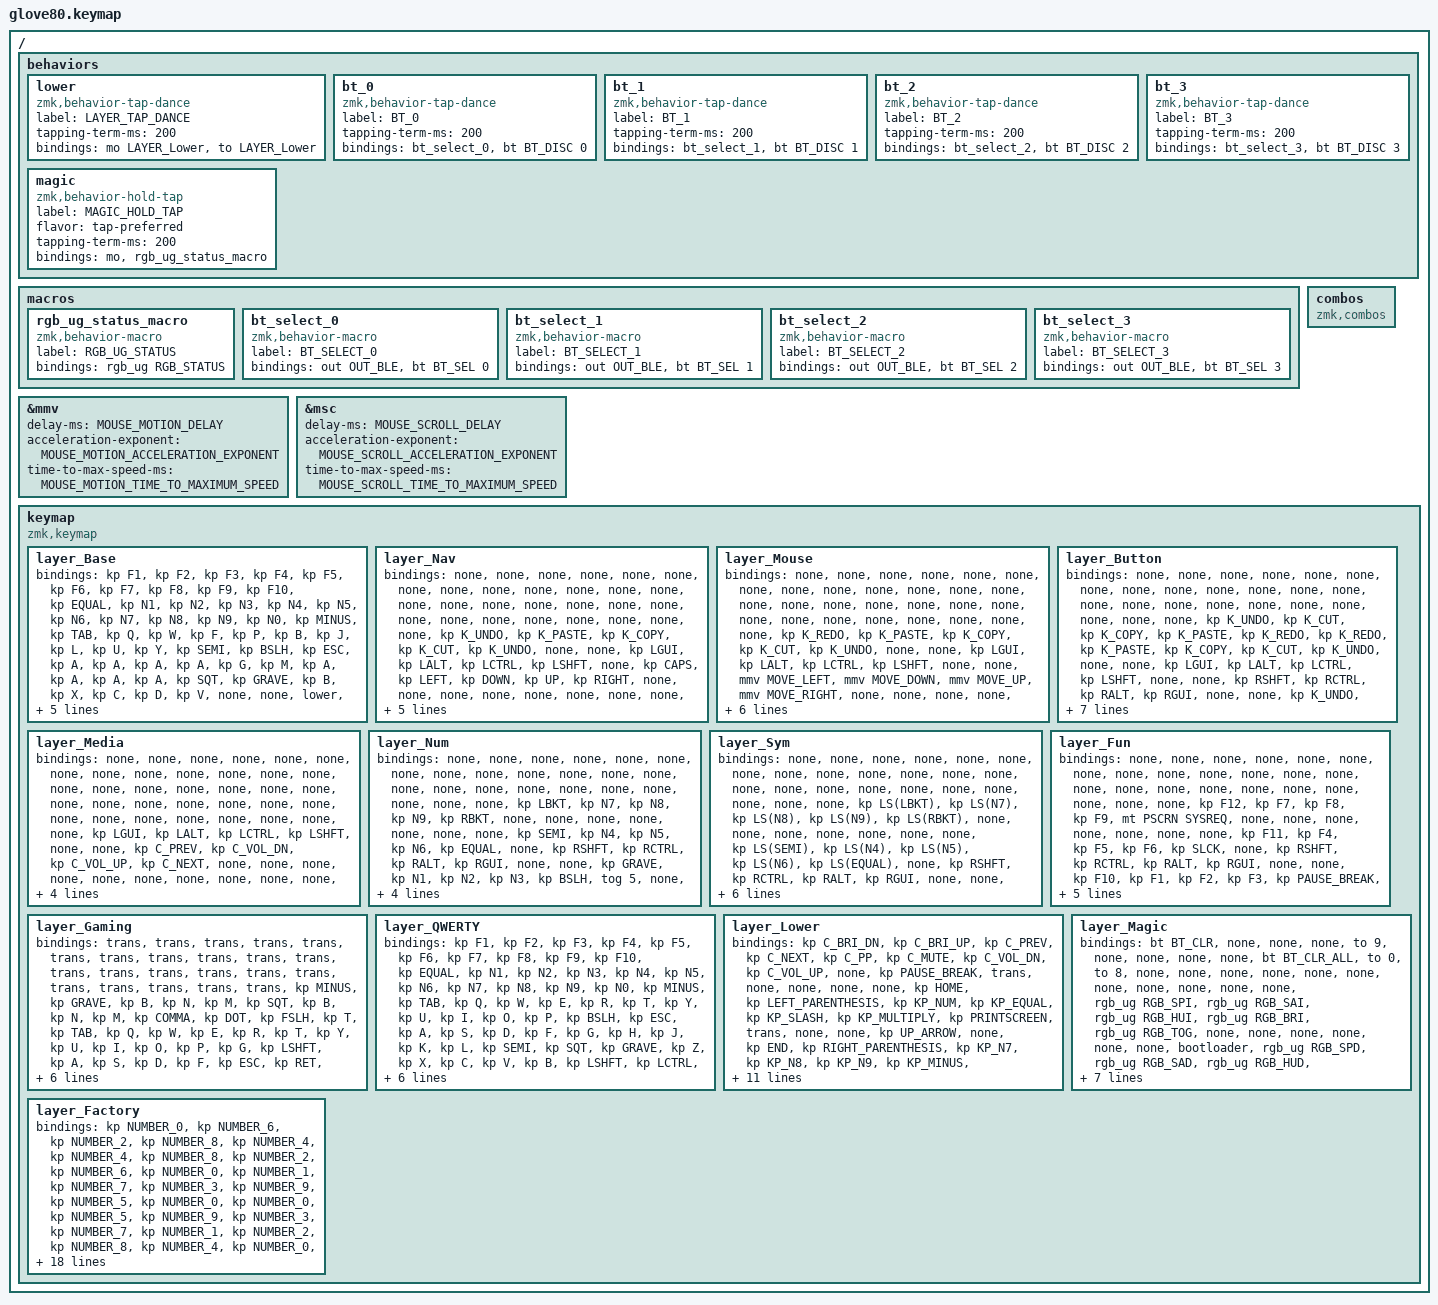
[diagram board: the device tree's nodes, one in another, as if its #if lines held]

/*
 * Copyright (c) 2020 The ZMK Contributors
 * Copyright (c) 2023 Innaworks Development Limited, trading as MoErgo
 *
 * SPDX-License-Identifier: MIT
 */


/* THIS FILE WAS GENERATED BY GLOVE80 LAYOUT EDITOR
 *
 * This file was generated automatically. You may or may not want to
 * edit it directly.
 */

#include <behaviors.dtsi>
/* Include all behavior includes needed */
#include <dt-bindings/zmk/outputs.h>
#include <dt-bindings/zmk/keys.h>
#include <dt-bindings/zmk/bt.h>
#include <dt-bindings/zmk/rgb.h>

/* Automatically generated layer name #define */
#define LAYER_Base 0
#define LAYER_Nav 1
#define LAYER_Mouse 2
#define LAYER_Button 3
#define LAYER_Media 4
#define LAYER_Num 5
#define LAYER_Sym 6
#define LAYER_Fun 7
#define LAYER_Gaming 8
#define LAYER_QWERTY 9
#define LAYER_Lower 10
#define LAYER_Magic 11
#define LAYER_Factory 12

/* To deal with the situation where there is no Lower layer, to keep &lower happy */
#ifndef LAYER_Lower
#define LAYER_Lower 0
#endif

/* Custom Device-tree */



/* Glove80 system behavior & macros */
/ {
    behaviors {
        // For the "layer" key, it'd nice to be able to use it as either a shift or a toggle.
        // Configure it as a tap dance, so the first tap (or hold) is a &mo and the second tap is a &to
        lower: lower {
            compatible = "zmk,behavior-tap-dance";
            label = "LAYER_TAP_DANCE";
            #binding-cells = <0>;
            tapping-term-ms = <200>;
            bindings = <&mo LAYER_Lower>, <&to LAYER_Lower>;
        };
    };
};

/ {
    macros {
        rgb_ug_status_macro: rgb_ug_status_macro {
            label = "RGB_UG_STATUS";
            compatible = "zmk,behavior-macro";
            #binding-cells = <0>;
            bindings
                = <&rgb_ug RGB_STATUS>;
        };
    };
};


/ {
#ifdef BT_DISC_CMD
    behaviors {
        bt_0: bt_0 {
            compatible = "zmk,behavior-tap-dance";
            label = "BT_0";
            #binding-cells = <0>;
            tapping-term-ms = <200>;
            bindings = <&bt_select_0>, <&bt BT_DISC 0>;
        };
        bt_1: bt_1 {
            compatible = "zmk,behavior-tap-dance";
            label = "BT_1";
            #binding-cells = <0>;
            tapping-term-ms = <200>;
            bindings = <&bt_select_1>, <&bt BT_DISC 1>;
        };
        bt_2: bt_2 {
            compatible = "zmk,behavior-tap-dance";
            label = "BT_2";
            #binding-cells = <0>;
            tapping-term-ms = <200>;
            bindings = <&bt_select_2>, <&bt BT_DISC 2>;
        };
        bt_3: bt_3 {
            compatible = "zmk,behavior-tap-dance";
            label = "BT_3";
            #binding-cells = <0>;
            tapping-term-ms = <200>;
            bindings = <&bt_select_3>, <&bt BT_DISC 3>;
        };
    };
    macros {
        bt_select_0: bt_select_0 {
            label = "BT_SELECT_0";
            compatible = "zmk,behavior-macro";
            #binding-cells = <0>;
            bindings
                = <&out OUT_BLE>,
                  <&bt BT_SEL 0>;
        };
        bt_select_1: bt_select_1 {
            label = "BT_SELECT_1";
            compatible = "zmk,behavior-macro";
            #binding-cells = <0>;
            bindings
                = <&out OUT_BLE>,
                  <&bt BT_SEL 1>;
        };
        bt_select_2: bt_select_2 {
            label = "BT_SELECT_2";
            compatible = "zmk,behavior-macro";
            #binding-cells = <0>;
            bindings
                = <&out OUT_BLE>,
                  <&bt BT_SEL 2>;
        };
        bt_select_3: bt_select_3 {
            label = "BT_SELECT_3";
            compatible = "zmk,behavior-macro";
            #binding-cells = <0>;
            bindings
                = <&out OUT_BLE>,
                  <&bt BT_SEL 3>;
        };
    };
#else
    macros {
        bt_0: bt_0 {
            label = "BT_0";
            compatible = "zmk,behavior-macro";
            #binding-cells = <0>;
            bindings
                = <&out OUT_BLE>,
                  <&bt BT_SEL 0>;
        };
        bt_1: bt_1 {
            label = "BT_1";
            compatible = "zmk,behavior-macro";
            #binding-cells = <0>;
            bindings
                = <&out OUT_BLE>,
                  <&bt BT_SEL 1>;
        };
        bt_2: bt_2 {
            label = "BT_2";
            compatible = "zmk,behavior-macro";
            #binding-cells = <0>;
            bindings
                = <&out OUT_BLE>,
                  <&bt BT_SEL 2>;
        };
        bt_3: bt_3 {
            label = "BT_3";
            compatible = "zmk,behavior-macro";
            #binding-cells = <0>;
            bindings
                = <&out OUT_BLE>,
                  <&bt BT_SEL 3>;
        };
    };
#endif
};

/ {
    behaviors {
        magic: magic {
            compatible = "zmk,behavior-hold-tap";
            label = "MAGIC_HOLD_TAP";
            #binding-cells = <2>;
            flavor = "tap-preferred";
            tapping-term-ms = <200>;
            bindings = <&mo>, <&rgb_ug_status_macro>;
        };
    };
};

/* #define for key positions */
#define POS_LH_T1 52
#define POS_LH_T2 53
#define POS_LH_T3 54
#define POS_LH_T4 69
#define POS_LH_T5 70
#define POS_LH_T6 71
#define POS_LH_C1R2 15
#define POS_LH_C1R3 27
#define POS_LH_C1R4 39
#define POS_LH_C1R5 51
#define POS_LH_C2R1 4
#define POS_LH_C2R2 14
#define POS_LH_C2R3 26
#define POS_LH_C2R4 38
#define POS_LH_C2R5 50
#define POS_LH_C2R6 68
#define POS_LH_C3R1 3
#define POS_LH_C3R2 13
#define POS_LH_C3R3 25
#define POS_LH_C3R4 37
#define POS_LH_C3R5 49
#define POS_LH_C3R6 67
#define POS_LH_C4R1 2
#define POS_LH_C4R2 12
#define POS_LH_C4R3 24
#define POS_LH_C4R4 36
#define POS_LH_C4R5 48
#define POS_LH_C4R6 66
#define POS_LH_C5R1 1
#define POS_LH_C5R2 11
#define POS_LH_C5R3 23
#define POS_LH_C5R4 35
#define POS_LH_C5R5 47
#define POS_LH_C5R6 65
#define POS_LH_C6R1 0
#define POS_LH_C6R2 10
#define POS_LH_C6R3 22
#define POS_LH_C6R4 34
#define POS_LH_C6R5 46
#define POS_LH_C6R6 64
#define POS_RH_T1 57
#define POS_RH_T2 56
#define POS_RH_T3 55
#define POS_RH_T4 74
#define POS_RH_T5 73
#define POS_RH_T6 72
#define POS_RH_C1R2 16
#define POS_RH_C1R3 28
#define POS_RH_C1R4 40
#define POS_RH_C1R5 58
#define POS_RH_C2R1 5
#define POS_RH_C2R2 17
#define POS_RH_C2R3 29
#define POS_RH_C2R4 41
#define POS_RH_C2R5 59
#define POS_RH_C2R6 75
#define POS_RH_C3R1 6
#define POS_RH_C3R2 18
#define POS_RH_C3R3 30
#define POS_RH_C3R4 42
#define POS_RH_C3R5 60
#define POS_RH_C3R6 76
#define POS_RH_C4R1 7
#define POS_RH_C4R2 19
#define POS_RH_C4R3 31
#define POS_RH_C4R4 43
#define POS_RH_C4R5 61
#define POS_RH_C4R6 77
#define POS_RH_C5R1 8
#define POS_RH_C5R2 20
#define POS_RH_C5R3 32
#define POS_RH_C5R4 44
#define POS_RH_C5R5 62
#define POS_RH_C5R6 78
#define POS_RH_C6R1 9
#define POS_RH_C6R2 21
#define POS_RH_C6R3 33
#define POS_RH_C6R4 45
#define POS_RH_C6R5 63
#define POS_RH_C6R6 79

/* Custom Defined Behaviors */
/ {
//////////////////////////////////////////////////////////////////////////
//
// Mouse keys (control mouse via keyboard) -- requires PR23 beta firmware:
// select "community.pr23.mouse-keys" from the drop-down menu located at
// Glove80 Layout Editor > Settings > Advanced Settings > Firmware Version
//
// - https://github.com/moergo-sc/zmk/pull/23
// - https://gist.github.com/krissen/dd27082e7ab0575619c7a31f4d2ec7ae
// - https://github.com/zmkfirmware/zmk/compare/main...urob:zmk:mouse-3.2
//
//////////////////////////////////////////////////////////////////////////

//
// MOUSE_MOTION_DELAY defines how long to wait (milliseconds) before starting
// to move the mouse pointer.
//
#ifndef MOUSE_MOTION_DELAY
#define MOUSE_MOTION_DELAY 0
#endif

//
// MOUSE_MOTION_ACCELERATION_EXPONENT sets how the mouse pointer accelerates:
//
// acceleration exponent 0: uniform speed
// acceleration exponent 1: uniform acceeration
// acceleration exponent 2: uniform jerk
//
#ifndef MOUSE_MOTION_ACCELERATION_EXPONENT
#define MOUSE_MOTION_ACCELERATION_EXPONENT 1
#endif

//
// MOUSE_MOTION_TIME_TO_MAXIMUM_SPEED defines how long to wait (milliseconds)
// before the mouse pointer speed is suddenly boosted to the maximum value.
//
#ifndef MOUSE_MOTION_TIME_TO_MAXIMUM_SPEED
#define MOUSE_MOTION_TIME_TO_MAXIMUM_SPEED 300
#endif

//
// MOUSE_MOTION_MAXIMUM_SPEED defines how quickly the mouse pointer can move.
//
#ifndef MOUSE_MOTION_MAXIMUM_SPEED
#define MOUSE_MOTION_MAXIMUM_SPEED 600
#endif

//
// MOUSE_SCROLL_DELAY defines how long to wait (milliseconds) before starting
// to move the mouse pointer.
//
#ifndef MOUSE_SCROLL_DELAY
#define MOUSE_SCROLL_DELAY 0
#endif

//
// MOUSE_SCROLL_ACCELERATION_EXPONENT sets how the mouse pointer accelerates:
//
// acceleration exponent 0: uniform speed
// acceleration exponent 1: uniform acceleration
// acceleration exponent 2: uniform jerk
//
#ifndef MOUSE_SCROLL_ACCELERATION_EXPONENT
#define MOUSE_SCROLL_ACCELERATION_EXPONENT 0
#endif

//
// MOUSE_SCROLL_TIME_TO_MAXIMUM_SPEED defines how long to wait (milliseconds)
// before the mouse pointer speed is suddenly boosted to the maximum value.
//
#ifndef MOUSE_SCROLL_TIME_TO_MAXIMUM_SPEED
#define MOUSE_SCROLL_TIME_TO_MAXIMUM_SPEED 300
#endif

//
// MOUSE_SCROLL_MAXIMUM_SPEED defines how quickly the mouse wheel can scroll.
//
#ifndef MOUSE_SCROLL_MAXIMUM_SPEED
#define MOUSE_SCROLL_MAXIMUM_SPEED 10
#endif

#if __has_include(<zmk/events/mouse_tick.h>)
  // ==== MOUSE-KEY <section begins> ====
  #define ZMK_MOUSE_DEFAULT_MOVE_VAL MOUSE_MOTION_MAXIMUM_SPEED
  #define ZMK_MOUSE_DEFAULT_SCRL_VAL MOUSE_SCROLL_MAXIMUM_SPEED
  #include <dt-bindings/zmk/mouse.h>
  &mmv {
    delay-ms = <MOUSE_MOTION_DELAY>;
    acceleration-exponent = <MOUSE_MOTION_ACCELERATION_EXPONENT>;
    time-to-max-speed-ms = <MOUSE_MOTION_TIME_TO_MAXIMUM_SPEED>;
  };
  &msc {
    delay-ms = <MOUSE_SCROLL_DELAY>;
    acceleration-exponent = <MOUSE_SCROLL_ACCELERATION_EXPONENT>;
    time-to-max-speed-ms = <MOUSE_SCROLL_TIME_TO_MAXIMUM_SPEED>;
  };
  // ==== MOUSE-KEY <section ends> =====
#else
  #define mkp none
  #define mmv none
  #define msc none
  #define LCLK
  #define MCLK
  #define RCLK
  #define MB1
  #define MB2
  #define MB3
  #define MB4
  #define MB5
  #define MB6
  #define MB7
  #define MB8
  #define MOVE_UP
  #define MOVE_DOWN
  #define MOVE_LEFT
  #define MOVE_RIGHT
  #define SCRL_UP
  #define SCRL_DOWN
  #define SCRL_LEFT
  #define SCRL_RIGHT
#endif
};

/* Automatically generated macro definitions */
/ {
    macros {

    };
};

/* Automatically generated behavior definitions */
/ {
    behaviors {
    
    };
};

/* Automatically generated combos definitions */
/ {
    combos {
    compatible = "zmk,combos";
    };
};

/* Automatically generated keymap */
/ {
    keymap {
        compatible = "zmk,keymap";


        layer_Base {
            bindings = <
               &kp F1    &kp F2   &kp F3    &kp F4     &kp F5                                                                  &kp F6     &kp F7    &kp F8    &kp F9    &kp F10
            &kp EQUAL    &kp N1   &kp N2    &kp N3     &kp N4  &kp N5                                                  &kp N6  &kp N7     &kp N8    &kp N9    &kp N0  &kp MINUS
              &kp TAB     &kp Q    &kp W     &kp F      &kp P   &kp B                                                   &kp J   &kp L      &kp U     &kp Y  &kp SEMI   &kp BSLH
              &kp ESC     &kp A    &kp A     &kp A      &kp A   &kp G                                                   &kp M   &kp A      &kp A     &kp A     &kp A    &kp SQT
            &kp GRAVE     &kp B    &kp X     &kp C      &kp D   &kp V   &none   &none  &lower   &none   &none   &none   &kp K   &kp H  &kp COMMA   &kp DOT     &kp A  &kp PG_UP
 &magic LAYER_Magic 0  &kp HOME  &kp END  &kp LEFT  &kp RIGHT           &kp A   &kp A   &kp A   &kp A   &kp A   &kp A          &kp UP   &kp DOWN  &kp LBKT  &kp RBKT  &kp PG_DN
            >;
        };

        layer_Nav {
            bindings = <
  &none     &none     &none      &none      &none                                                                                &none       &none      &none       &none   &none
  &none     &none     &none      &none      &none   &none                                                           &none        &none       &none      &none       &none   &none
  &none     &none     &none      &none      &none   &none                                                      &kp K_UNDO  &kp K_PASTE  &kp K_COPY  &kp K_CUT  &kp K_UNDO   &none
  &none  &kp LGUI  &kp LALT  &kp LCTRL  &kp LSHFT   &none                                                        &kp CAPS     &kp LEFT    &kp DOWN     &kp UP   &kp RIGHT   &none
  &none     &none     &none      &none      &none   &none   &none   &none   &none    &none    &none    &tog 1     &kp INS     &kp HOME   &kp PG_DN  &kp PG_UP     &kp END   &none
  &none     &none     &none      &none      &none           &none   &none   &none  &kp DEL  &kp RET  &kp BSPC                    &none       &none      &none       &none   &none
            >;
        };

        layer_Mouse {
            bindings = <
                &none     &none     &none      &none      &none                                                                                        &none           &none         &none            &none   &none
                &none     &none     &none      &none      &none   &none                                                                &none           &none           &none         &none            &none   &none
                &none     &none     &none      &none      &none   &none                                                           &kp K_REDO     &kp K_PASTE      &kp K_COPY     &kp K_CUT       &kp K_UNDO   &none
                &none  &kp LGUI  &kp LALT  &kp LCTRL  &kp LSHFT   &none                                                                &none  &mmv MOVE_LEFT  &mmv MOVE_DOWN  &mmv MOVE_UP  &mmv MOVE_RIGHT   &none
                &none     &none     &none      &none      &none   &none   &none   &none   &none      &none      &none     &tog 2       &none  &msc SCRL_LEFT  &msc SCRL_DOWN  &msc SCRL_UP  &msc SCRL_RIGHT   &none
 &magic LAYER_Magic 0     &none     &none      &none      &none           &none   &none   &none  &mkp MCLK  &mkp RCLK  &mkp LCLK                       &none           &none         &none            &none   &none
            >;
        };

        layer_Button {
            bindings = <
  &none       &none      &none       &none        &none                                                                                                  &none       &none      &none       &none   &none
  &none       &none      &none       &none        &none       &none                                                                         &none        &none       &none      &none       &none   &none
  &none  &kp K_UNDO  &kp K_CUT  &kp K_COPY  &kp K_PASTE  &kp K_REDO                                                                    &kp K_REDO  &kp K_PASTE  &kp K_COPY  &kp K_CUT  &kp K_UNDO   &none
  &none    &kp LGUI   &kp LALT   &kp LCTRL    &kp LSHFT       &none                                                                         &none    &kp RSHFT   &kp RCTRL   &kp RALT    &kp RGUI   &none
  &none  &kp K_UNDO  &kp K_CUT  &kp K_COPY  &kp K_PASTE  &kp K_REDO     &tog 3      &none      &none      &none      &none     &tog 3  &kp K_REDO  &kp K_PASTE  &kp K_COPY  &kp K_CUT  &kp K_UNDO   &none
  &none       &none      &none       &none        &none              &mkp LCLK  &mkp RCLK  &mkp MCLK  &mkp MCLK  &mkp RCLK  &mkp LCLK                    &none       &none      &none       &none   &none
            >;
        };

        layer_Media {
            bindings = <
  &none     &none     &none      &none      &none                                                                                 &none         &none         &none       &none   &none
  &none     &none     &none      &none      &none   &none                                                             &none       &none         &none         &none       &none   &none
  &none     &none     &none      &none      &none   &none                                                             &none       &none         &none         &none       &none   &none
  &none  &kp LGUI  &kp LALT  &kp LCTRL  &kp LSHFT   &none                                                             &none  &kp C_PREV  &kp C_VOL_DN  &kp C_VOL_UP  &kp C_NEXT   &none
  &none     &none     &none      &none      &none   &none   &none   &none   &none       &none     &none      &tog 4   &none       &none         &none         &none       &none   &none
  &none     &none     &none      &none      &none           &none   &none   &none  &kp C_STOP  &kp C_PP  &kp C_MUTE               &none         &none         &none       &none   &none
            >;
        };

        layer_Num {
            bindings = <
  &none      &none   &none   &none   &none                                                                             &none      &none     &none     &none   &none
  &none      &none   &none   &none   &none      &none                                                       &none      &none      &none     &none     &none   &none
  &none   &kp LBKT  &kp N7  &kp N8  &kp N9   &kp RBKT                                                       &none      &none      &none     &none     &none   &none
  &none   &kp SEMI  &kp N4  &kp N5  &kp N6  &kp EQUAL                                                       &none  &kp RSHFT  &kp RCTRL  &kp RALT  &kp RGUI   &none
  &none  &kp GRAVE  &kp N1  &kp N2  &kp N3   &kp BSLH   &tog 5   &none      &none   &none   &none   &none   &none      &none      &none     &none     &none   &none
  &none      &none   &none   &none   &none             &kp DOT  &kp N0  &kp MINUS   &none   &none   &none              &none      &none     &none     &none   &none
            >;
        };

        layer_Sym {
            bindings = <
  &none          &none       &none       &none       &none                                                                                            &none      &none     &none     &none   &none
  &none          &none       &none       &none       &none          &none                                                                  &none      &none      &none     &none     &none   &none
  &none   &kp LS(LBKT)  &kp LS(N7)  &kp LS(N8)  &kp LS(N9)   &kp LS(RBKT)                                                                  &none      &none      &none     &none     &none   &none
  &none   &kp LS(SEMI)  &kp LS(N4)  &kp LS(N5)  &kp LS(N6)  &kp LS(EQUAL)                                                                  &none  &kp RSHFT  &kp RCTRL  &kp RALT  &kp RGUI   &none
  &none  &kp LS(GRAVE)  &kp LS(N1)  &kp LS(N2)  &kp LS(N3)   &kp LS(BSLH)      &tog 6       &none          &none   &none   &none   &none   &none      &none      &none     &none     &none   &none
  &none          &none       &none       &none       &none                 &kp LS(N9)  &kp LS(N0)  &kp LS(MINUS)   &none   &none   &none              &none      &none     &none     &none   &none
            >;
        };

        layer_Fun {
            bindings = <
  &none    &none   &none   &none   &none                                                                                       &none      &none     &none     &none   &none
  &none    &none   &none   &none   &none             &none                                                          &none      &none      &none     &none     &none   &none
  &none  &kp F12  &kp F7  &kp F8  &kp F9  &mt PSCRN SYSREQ                                                          &none      &none      &none     &none     &none   &none
  &none  &kp F11  &kp F4  &kp F5  &kp F6          &kp SLCK                                                          &none  &kp RSHFT  &kp RCTRL  &kp RALT  &kp RGUI   &none
  &none  &kp F10  &kp F1  &kp F2  &kp F3   &kp PAUSE_BREAK     &tog 7      &none    &none   &none   &none   &none   &none      &none      &none     &none     &none   &none
  &none    &none   &none   &none   &none                    &kp K_APP  &kp SPACE  &kp TAB   &none   &none   &none              &none      &none     &none     &none   &none
            >;
        };

        layer_Gaming {
            bindings = <
    &trans     &trans  &trans  &trans  &trans                                                                                    &trans  &trans     &trans   &trans                &trans
    &trans     &trans  &trans  &trans  &trans   &trans                                                                   &trans  &trans  &trans     &trans   &trans                &trans
 &kp MINUS  &kp GRAVE   &kp B   &kp N   &kp M  &kp SQT                                                                    &kp B   &kp N   &kp M  &kp COMMA  &kp DOT              &kp FSLH
     &kp T    &kp TAB   &kp Q   &kp W   &kp E    &kp R                                                                    &kp T   &kp Y   &kp U      &kp I    &kp O                 &kp P
     &kp G  &kp LSHFT   &kp A   &kp S   &kp D    &kp F    &kp ESC   &kp RET  &kp PAUSE_BREAK  &kp BSPC  &kp DEL  &trans   &kp G   &kp H   &kp J      &kp K    &kp L              &kp SEMI
     &kp V  &kp LCTRL   &kp Z   &kp X   &kp C           &kp SPACE  &kp LALT         &kp LGUI    &lower   &trans  &trans          &trans  &trans     &trans   &trans  &magic LAYER_Magic 0
            >;
        };

        layer_QWERTY {
            bindings = <
               &kp F1    &kp F2   &kp F3    &kp F4     &kp F5                                                                                  &kp F6     &kp F7    &kp F8    &kp F9    &kp F10
            &kp EQUAL    &kp N1   &kp N2    &kp N3     &kp N4  &kp N5                                                                  &kp N6  &kp N7     &kp N8    &kp N9    &kp N0  &kp MINUS
              &kp TAB     &kp Q    &kp W     &kp E      &kp R   &kp T                                                                   &kp Y   &kp U      &kp I     &kp O     &kp P   &kp BSLH
              &kp ESC     &kp A    &kp S     &kp D      &kp F   &kp G                                                                   &kp H   &kp J      &kp K     &kp L  &kp SEMI    &kp SQT
            &kp GRAVE     &kp Z    &kp X     &kp C      &kp V   &kp B  &kp LSHFT  &kp LCTRL    &lower  &kp LGUI  &kp RCTRL  &kp RSHFT   &kp N   &kp M  &kp COMMA   &kp DOT  &kp FSLH  &kp PG_UP
 &magic LAYER_Magic 0  &kp HOME  &kp END  &kp LEFT  &kp RIGHT           &kp BSPC    &kp DEL  &kp LALT  &kp RALT    &kp RET  &kp SPACE          &kp UP   &kp DOWN  &kp LBKT  &kp RBKT  &kp PG_DN
            >;
        };

        layer_Lower {
            bindings = <
         &kp C_BRI_DN  &kp C_BRI_UP      &kp C_PREV      &kp C_NEXT         &kp C_PP                                                                                    &kp C_MUTE  &kp C_VOL_DN  &kp C_VOL_UP            &none  &kp PAUSE_BREAK
               &trans         &none           &none           &none            &none   &kp HOME                                                   &kp LEFT_PARENTHESIS  &kp KP_NUM  &kp KP_EQUAL  &kp KP_SLASH  &kp KP_MULTIPLY  &kp PRINTSCREEN
               &trans         &none           &none    &kp UP_ARROW            &none    &kp END                                                  &kp RIGHT_PARENTHESIS   &kp KP_N7     &kp KP_N8     &kp KP_N9     &kp KP_MINUS   &kp SCROLLLOCK
               &trans         &none  &kp LEFT_ARROW  &kp DOWN_ARROW  &kp RIGHT_ARROW  &kp PG_UP                                                            &kp PERCENT   &kp KP_N4     &kp KP_N5     &kp KP_N6      &kp KP_PLUS            &none
               &trans     &kp K_APP           &none         &kp F11          &kp F12  &kp PG_DN  &trans  &trans   &to 0  &trans  &trans  &trans              &kp COMMA   &kp KP_N1     &kp KP_N2     &kp KP_N3     &kp KP_ENTER           &trans
 &magic LAYER_Magic 0      &kp CAPS         &kp INS         &kp F11          &kp F12             &trans  &trans  &trans  &trans  &trans  &trans                          &kp KP_N0     &kp KP_N0    &kp KP_DOT     &kp KP_ENTER           &trans
            >;
        };

        layer_Magic {
            bindings = <
  &bt BT_CLR            &none            &none            &none            &to 9                                                                                  &none   &none   &none   &none  &bt BT_CLR_ALL
       &to 0            &to 8            &none            &none            &none            &none                                                         &none   &none   &none   &none   &none           &none
       &none  &rgb_ug RGB_SPI  &rgb_ug RGB_SAI  &rgb_ug RGB_HUI  &rgb_ug RGB_BRI  &rgb_ug RGB_TOG                                                         &none   &none   &none   &none   &none           &none
 &bootloader  &rgb_ug RGB_SPD  &rgb_ug RGB_SAD  &rgb_ug RGB_HUD  &rgb_ug RGB_BRD  &rgb_ug RGB_EFF                                                         &none   &none   &none   &none   &none     &bootloader
  &sys_reset            &none            &none            &none            &none            &none   &bt_2   &bt_3         &none   &none   &none   &none   &none   &none   &none   &none   &none      &sys_reset
       &none            &none            &none            &none            &none                    &bt_0   &bt_1  &out OUT_USB   &none   &none   &none           &none   &none   &none   &none           &none
            >;
        };

        layer_Factory {
            bindings = <
 &kp NUMBER_0  &kp NUMBER_6  &kp NUMBER_2  &kp NUMBER_8  &kp NUMBER_4                                                                                                                  &kp NUMBER_4  &kp NUMBER_8  &kp NUMBER_2  &kp NUMBER_6  &kp NUMBER_0
 &kp NUMBER_1  &kp NUMBER_7  &kp NUMBER_3  &kp NUMBER_9  &kp NUMBER_5  &kp NUMBER_0                                                                                      &kp NUMBER_0  &kp NUMBER_5  &kp NUMBER_9  &kp NUMBER_3  &kp NUMBER_7  &kp NUMBER_1
 &kp NUMBER_2  &kp NUMBER_8  &kp NUMBER_4  &kp NUMBER_0  &kp NUMBER_6  &kp NUMBER_1                                                                                      &kp NUMBER_1  &kp NUMBER_6  &kp NUMBER_0  &kp NUMBER_4  &kp NUMBER_8  &kp NUMBER_2
 &kp NUMBER_3  &kp NUMBER_9  &kp NUMBER_5  &kp NUMBER_1  &kp NUMBER_7  &kp NUMBER_2                                                                                      &kp NUMBER_2  &kp NUMBER_7  &kp NUMBER_1  &kp NUMBER_5  &kp NUMBER_9  &kp NUMBER_3
 &kp NUMBER_4  &kp NUMBER_0  &kp NUMBER_6  &kp NUMBER_2  &kp NUMBER_8  &kp NUMBER_3  &kp NUMBER_4  &kp NUMBER_5  &kp NUMBER_6  &kp NUMBER_6  &kp NUMBER_5  &kp NUMBER_4  &kp NUMBER_3  &kp NUMBER_8  &kp NUMBER_2  &kp NUMBER_6  &kp NUMBER_0  &kp NUMBER_4
 &kp NUMBER_5  &kp NUMBER_1  &kp NUMBER_7  &kp NUMBER_3  &kp NUMBER_9                &kp NUMBER_7  &kp NUMBER_8  &kp NUMBER_9  &kp NUMBER_9  &kp NUMBER_8  &kp NUMBER_7                &kp NUMBER_9  &kp NUMBER_3  &kp NUMBER_7  &kp NUMBER_1  &kp NUMBER_5
            >;
        };

    };
};
